# ATSAMG55J19 device description
Architecture: CORTEX-M4; Family: SAMG; Series: SAMG55
Registers are 32-bit, read-write, no defined reset value unless marked. A register's access mark holds for its fields unless they carry their own. Offsets are from the block's base; [hi:lo] are bit positions; {n}, {i} and the like mark numbered series.

## PIO — Parallel Input/Output Controller
Instances: PIOA 0x400E0E00, PIOB 0x400E1000
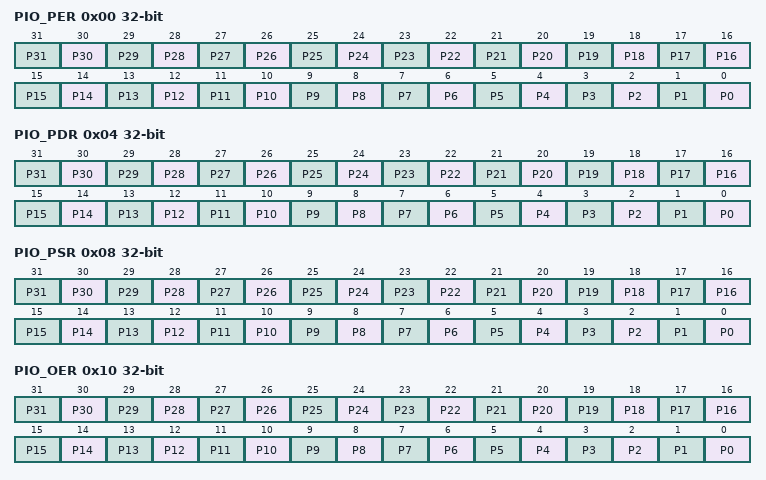
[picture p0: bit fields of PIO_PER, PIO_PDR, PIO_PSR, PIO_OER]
0x00 PIO_PER wo (atomic set of PIO_PSR) — Enable Register
  [n] P{n} (n=0..31) — Enable
0x04 PIO_PDR wo (atomic clear of PIO_PSR) — Disable Register
  [n] P{n} (n=0..31) — Disable
0x08 PIO_PSR ro — Status Register
  [n] P{n} (n=0..31) — Status
0x10 PIO_OER wo (atomic set of PIO_OSR) — Output Enable Register
  [n] P{n} (n=0..31) — Output Enable
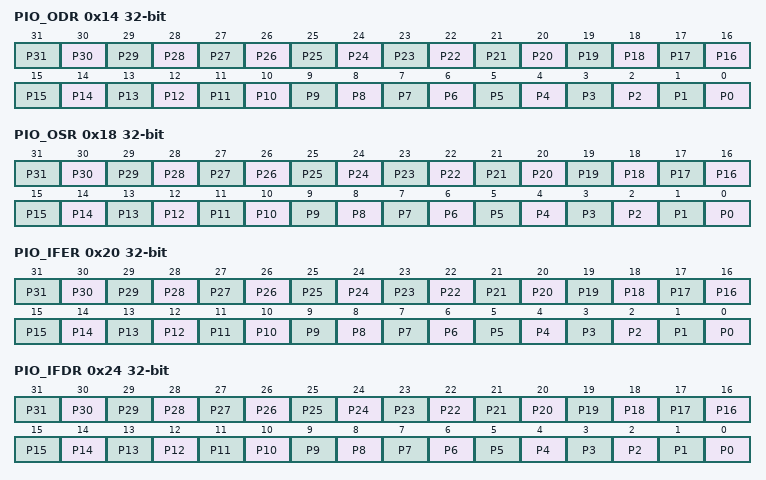
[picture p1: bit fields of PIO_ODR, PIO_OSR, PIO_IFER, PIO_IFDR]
0x14 PIO_ODR wo (atomic clear of PIO_OSR) — Output Disable Register
  [n] P{n} (n=0..31) — Output Disable
0x18 PIO_OSR ro — Output Status Register
  [n] P{n} (n=0..31) — Output Status
0x20 PIO_IFER wo (atomic set of PIO_IFSR) — Glitch Input Filter Enable Register
  [n] P{n} (n=0..31) — Input Filter Enable
0x24 PIO_IFDR wo (atomic clear of PIO_IFSR) — Glitch Input Filter Disable Register
  [n] P{n} (n=0..31) — Input Filter Disable
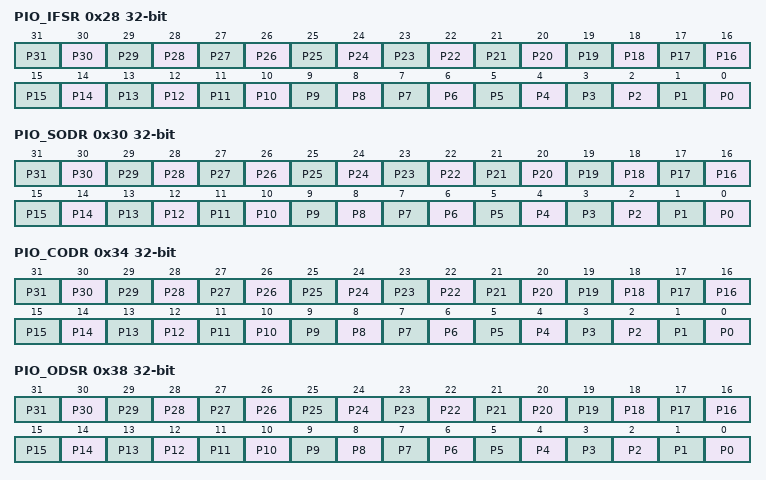
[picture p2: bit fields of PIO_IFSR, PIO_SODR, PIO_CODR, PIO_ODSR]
0x28 PIO_IFSR ro — Glitch Input Filter Status Register
  [n] P{n} (n=0..31) — Input Filter Status
0x30 PIO_SODR wo (atomic set of PIO_ODSR) — Set Output Data Register
  [n] P{n} (n=0..31) — Set Output Data
0x34 PIO_CODR wo (atomic clear of PIO_ODSR) — Clear Output Data Register
  [n] P{n} (n=0..31) — Clear Output Data
0x38 PIO_ODSR — Output Data Status Register
  [n] P{n} (n=0..31) — Output Data Status
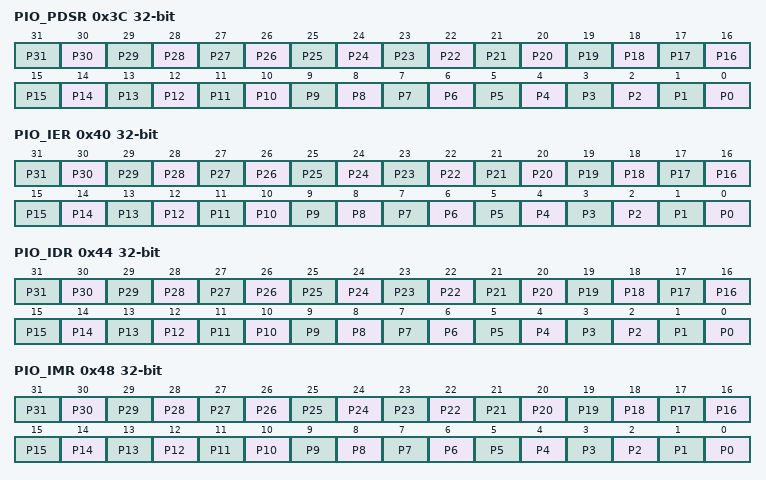
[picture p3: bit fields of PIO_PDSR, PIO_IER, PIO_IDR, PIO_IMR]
0x3C PIO_PDSR ro — Pin Data Status Register
  [n] P{n} (n=0..31) — Output Data Status
0x40 PIO_IER wo (atomic set of PIO_IMR) — Interrupt Enable Register
  [n] P{n} (n=0..31) — Input Change Interrupt Enable
0x44 PIO_IDR wo (atomic clear of PIO_IMR) — Interrupt Disable Register
  [n] P{n} (n=0..31) — Input Change Interrupt Disable
0x48 PIO_IMR ro (atomic read) — Interrupt Mask Register
  [n] P{n} (n=0..31) — Input Change Interrupt Mask
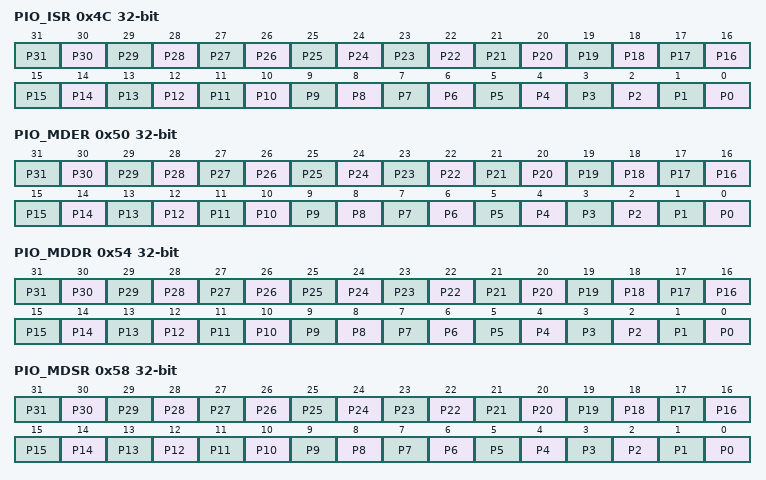
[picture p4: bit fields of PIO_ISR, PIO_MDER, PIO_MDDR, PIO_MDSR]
0x4C PIO_ISR ro (atomic read) — Interrupt Status Register
  [n] P{n} (n=0..31) — Input Change Interrupt Status
0x50 PIO_MDER wo (atomic set of PIO_MDSR) — Multi-driver Enable Register
  [n] P{n} (n=0..31) — Multi-drive Enable
0x54 PIO_MDDR wo (atomic clear of PIO_MDSR) — Multi-driver Disable Register
  [n] P{n} (n=0..31) — Multi-drive Disable
0x58 PIO_MDSR ro — Multi-driver Status Register
  [n] P{n} (n=0..31) — Multi-drive Status
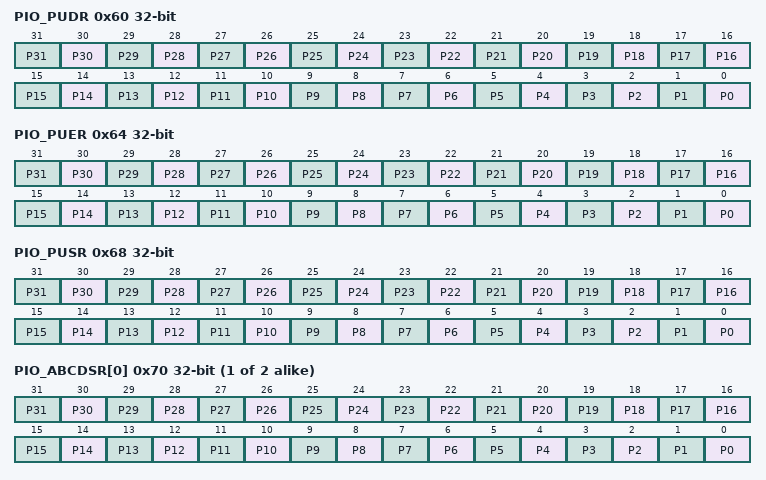
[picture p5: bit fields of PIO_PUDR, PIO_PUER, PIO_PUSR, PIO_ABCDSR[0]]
0x60 PIO_PUDR wo (atomic clear of PIO_PUSR) — Pull-up Disable Register
  [n] P{n} (n=0..31) — Pull-Up Disable
0x64 PIO_PUER wo (atomic set of PIO_PUSR) — Pull-up Enable Register
  [n] P{n} (n=0..31) — Pull-Up Enable
0x68 PIO_PUSR ro — Pad Pull-up Status Register
  [n] P{n} (n=0..31) — Pull-Up Status
{0x70+4i} PIO_ABCDSR[{i}] (i=0..1) — Peripheral Select Register 0
  [n] P{n} (n=0..31) — Peripheral Select
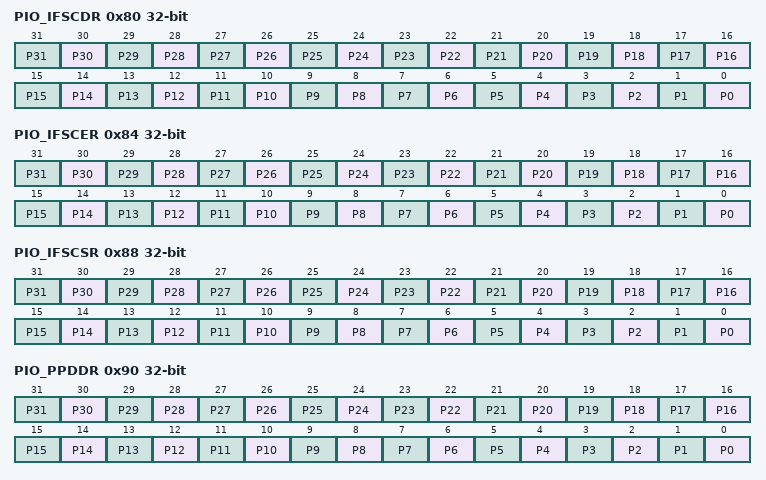
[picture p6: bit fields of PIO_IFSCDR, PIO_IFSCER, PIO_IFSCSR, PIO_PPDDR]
0x80 PIO_IFSCDR wo (atomic clear of PIO_IFSCSR) — Input Filter Slow Clock Disable Register
  [n] P{n} (n=0..31) — Peripheral Clock Glitch Filtering Select
0x84 PIO_IFSCER wo (atomic set of PIO_IFSCSR) — Input Filter Slow Clock Enable Register
  [n] P{n} (n=0..31) — Slow Clock Debouncing Filtering Select
0x88 PIO_IFSCSR ro — Input Filter Slow Clock Status Register
  [n] P{n} (n=0..31) — Glitch or Debouncing Filter Selection Status
0x8C PIO_SCDR — Slow Clock Divider Debouncing Register
  [13:0] DIV — Slow Clock Divider Selection for Debouncing
0x90 PIO_PPDDR wo (atomic clear of PIO_PPDSR) — Pad Pull-down Disable Register
  [n] P{n} (n=0..31) — Pull-Down Disable
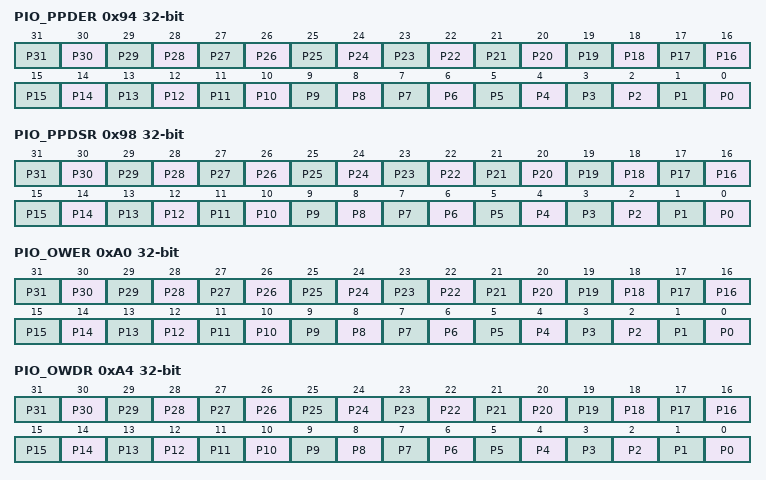
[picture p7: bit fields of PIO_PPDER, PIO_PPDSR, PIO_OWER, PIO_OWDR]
0x94 PIO_PPDER wo (atomic set of PIO_PPDSR) — Pad Pull-down Enable Register
  [n] P{n} (n=0..31) — Pull-Down Enable
0x98 PIO_PPDSR ro — Pad Pull-down Status Register
  [n] P{n} (n=0..31) — Pull-Down Status
0xA0 PIO_OWER wo (atomic set of PIO_OWSR) — Output Write Enable
  [n] P{n} (n=0..31) — Output Write Enable
0xA4 PIO_OWDR wo (atomic clear of PIO_OWSR) — Output Write Disable
  [n] P{n} (n=0..31) — Output Write Disable
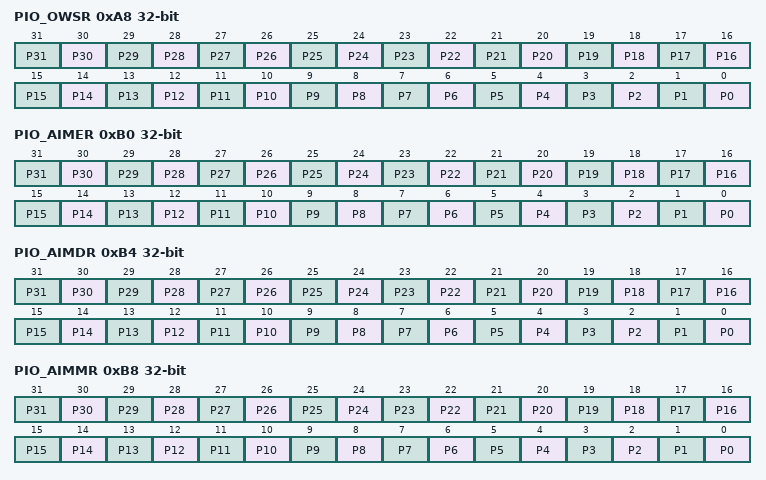
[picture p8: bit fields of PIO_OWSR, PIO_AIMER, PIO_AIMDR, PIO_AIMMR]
0xA8 PIO_OWSR ro — Output Write Status Register
  [n] P{n} (n=0..31) — Output Write Status
0xB0 PIO_AIMER wo (atomic set of PIO_AIMMR) — Additional Interrupt Modes Enable Register
  [n] P{n} (n=0..31) — Additional Interrupt Modes Enable
0xB4 PIO_AIMDR wo (atomic clear of PIO_AIMMR) — Additional Interrupt Modes Disable Register
  [n] P{n} (n=0..31) — Additional Interrupt Modes Disable
0xB8 PIO_AIMMR ro — Additional Interrupt Modes Mask Register
  [n] P{n} (n=0..31) — IO Line Index
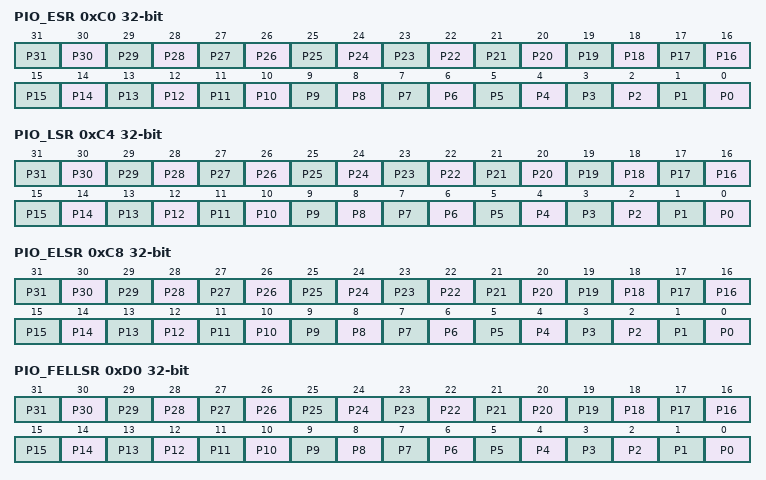
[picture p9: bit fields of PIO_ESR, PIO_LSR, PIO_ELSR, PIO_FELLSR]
0xC0 PIO_ESR wo (atomic clear of PIO_ELSR) — Edge Select Register
  [n] P{n} (n=0..31) — Edge Interrupt Selection
0xC4 PIO_LSR wo (atomic set of PIO_ELSR) — Level Select Register
  [n] P{n} (n=0..31) — Level Interrupt Selection
0xC8 PIO_ELSR ro — Edge/Level Status Register
  [n] P{n} (n=0..31) — Edge/Level Interrupt Source Selection
0xD0 PIO_FELLSR wo (atomic clear of PIO_FRLHSR) — Falling Edge/Low-Level Select Register
  [n] P{n} (n=0..31) — Falling Edge/Low-Level Interrupt Selection
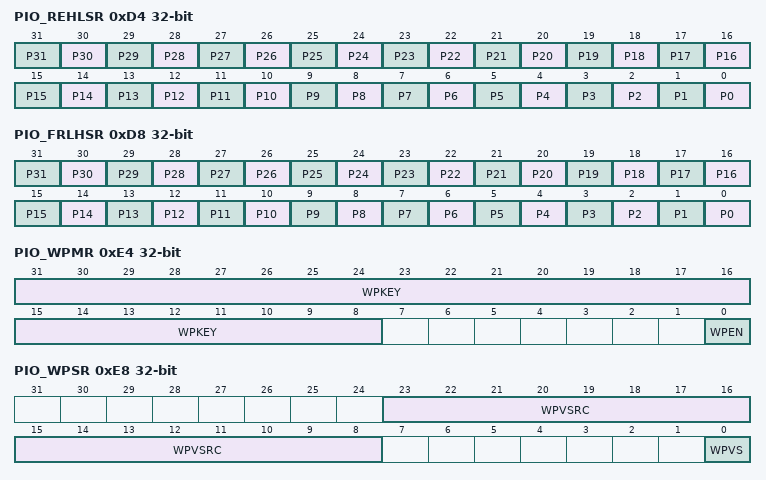
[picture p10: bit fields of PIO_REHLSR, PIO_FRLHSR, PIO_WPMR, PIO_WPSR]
0xD4 PIO_REHLSR wo (atomic set of PIO_FRLHSR) — Rising Edge/High-Level Select Register
  [n] P{n} (n=0..31) — Rising Edge/High-Level Interrupt Selection
0xD8 PIO_FRLHSR ro — Fall/Rise - Low/High Status Register
  [n] P{n} (n=0..31) — Edge/Level Interrupt Source Selection
0xE4 PIO_WPMR — Write Protection Mode Register
  [31:8] WPKEY — Write Protection Key
    0x50494F=PASSWD (Writing any other value in this field aborts the write operation of the WPEN bit. Always reads as 0.)
  [0] WPEN — Write Protection Enable
0xE8 PIO_WPSR ro — Write Protection Status Register
  [23:8] WPVSRC — Write Protection Violation Source
  [0] WPVS — Write Protection Violation Status
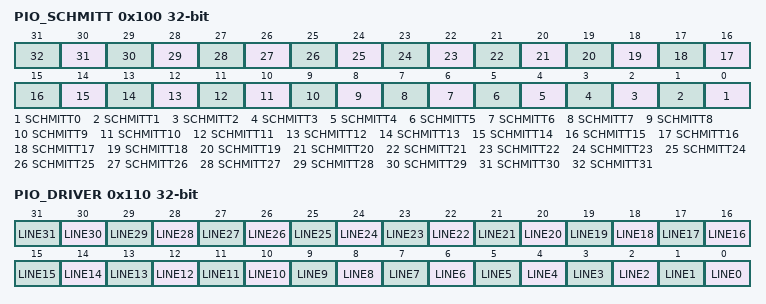
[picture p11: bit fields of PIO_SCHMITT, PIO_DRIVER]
0x100 PIO_SCHMITT — Schmitt Trigger Register
  [n] SCHMITT{n} (n=0..31) — Schmitt Trigger Control
0x110 PIO_DRIVER — I/O Drive Register
  [all] fields
    0=LOW_DRIVE (Lowest drive); 1=HIGH_DRIVE (Highest drive)
  [n] LINE{n} (n=0..31) — Drive of Line {n}
